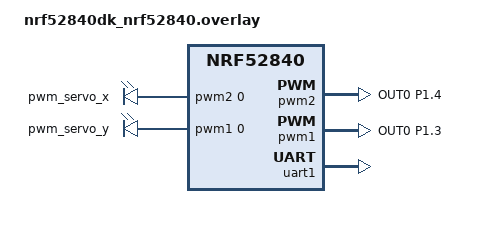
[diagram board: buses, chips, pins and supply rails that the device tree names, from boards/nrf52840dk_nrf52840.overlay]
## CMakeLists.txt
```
cmake_minimum_required(VERSION 3.20.0)
find_package(Zephyr REQUIRED HINTS $ENV{ZEPHYR_BASE})

SET(CMAKE_CXX_STANDARD 17)
SET(CMAKE_CXX_STANDARD_REQUIRED ON)

project(LIDAR_App)

target_sources(app PRIVATE src/main.cpp
                           src/servo.cpp
                           src/lidar.cpp
                           src/Ble.cpp
                           src/LidarService.cpp
)
```

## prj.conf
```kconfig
CONFIG_STDOUT_CONSOLE=y
CONFIG_PRINTK=y
CONFIG_PWM=y
CONFIG_LOG=y
CONFIG_LOG_PRINTK=y
CONFIG_LOG_MODE_IMMEDIATE=y
CONFIG_PWM_LOG_LEVEL_DBG=n

# Serial
CONFIG_UART_INTERRUPT_DRIVEN=y
CONFIG_UART_ASYNC_API=y

# Bluetooth
CONFIG_BT=y
CONFIG_BT_PERIPHERAL=y
CONFIG_BT_DEVICE_NAME="LIDAR_SCANNER"

# CPP
CONFIG_CPP=y
CONFIG_REQUIRES_FULL_LIBCPP=y
CONFIG_CPP_EXCEPTIONS=y
CONFIG_STD_CPP17=y
```

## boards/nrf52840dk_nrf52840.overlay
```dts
/ {
	aliases {
	  pwm-servo-x = &pwm_servo_x;
	  pwm-servo-y = &pwm_servo_y;
    };
  
	pwm-servo-x {
	  compatible = "pwm-leds";
	  pwm_servo_x: pwm_servo_x {
		pwms = <&pwm2 0 PWM_MSEC(20) PWM_POLARITY_NORMAL>;
	  };
	};

	pwm-servo-y {
	  compatible = "pwm-leds";
	  pwm_servo_y: pwm_servo_y {
		pwms = <&pwm1 0 PWM_MSEC(20) PWM_POLARITY_NORMAL>;
	  };
	};
  
  };
  
  &pinctrl {
    pwm1_default: pwm1_default {
        group1 {
            psels = <NRF_PSEL(PWM_OUT0, 1, 3)>;
        };
    };

    pwm2_default: pwm2_default {
        group1 {
            psels = <NRF_PSEL(PWM_OUT0, 1, 4)>;
        };
    };
  };
  
  &pwm2 {
	status = "okay";
	pinctrl-0 = <&pwm2_default>;
	pinctrl-names = "default";
  };

  &pwm1 {
	status = "okay";
	pinctrl-0 = <&pwm1_default>;
	pinctrl-names = "default";
  };

  &pwm0 {
  	status = "disabled";
  };

&uart1 {
	status = "okay";
};

&uart1_default {
	group2 {
		psels = <NRF_PSEL(UART_TX, 1, 6)>;
	};

	group1 {
		psels = <NRF_PSEL(UART_RX, 1, 7)>;
	};
};
```

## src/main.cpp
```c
#include <zephyr/kernel.h>
#include <zephyr/sys/printk.h>
#include <zephyr/device.h>
#include <zephyr/logging/log.h>

#include "../hdr/servo.hpp"
#include "../hdr/lidar.hpp"
#include "../hdr/Ble.h"

#include <vector>
#include <string.h>
#include <string>
#include <sstream>
#include <memory>

LOG_MODULE_REGISTER(main, LOG_LEVEL_INF);

static volatile bool isConnected = false;

std::vector<uint8_t> StructToByteVector(void *structPointer, size_t sizeOfStruct)
{
	std::vector<uint8_t> returnVector;
	returnVector.resize(sizeOfStruct);
	memcpy(&returnVector[0],structPointer,sizeOfStruct); 
	
	return returnVector;
}

const std::vector<uint8_t> vector_to_be_received = {10, 11, 12, 13, 14, 15, 16, 17};

void configCallback(std::vector<uint8_t> data)
{        

	if(data.size() != 8){
			LOG_ERR("Wrong data size\n");
			return;
	}

	for (size_t i = 0; i < vector_to_be_received.size(); ++i)
	{
		if (vector_to_be_received[i] != data[i])
		{
			LOG_INF("Device Parred Incorrectly");
			return;
		}
		LOG_INF("Byte received: %d", data[i]);
	}

	LOG_INF("Device Parred Correctly");
	isConnected = true;
}

int main(void)
{
	pwm_dt_spec pwm_servo_x = PWM_DT_SPEC_GET(DT_ALIAS(pwm_servo_x));
	std::unique_ptr<Servo> servo_x = std::make_unique<Servo>(pwm_servo_x);

	pwm_dt_spec pwm_servo_y = PWM_DT_SPEC_GET(DT_ALIAS(pwm_servo_y));
	std::unique_ptr<Servo> servo_y = std::make_unique<Servo>(pwm_servo_y);

	const struct device *uart_device = DEVICE_DT_GET(DT_NODELABEL(uart1));
	std::unique_ptr<Lidar> lidar = std::make_unique<Lidar>(uart_device);

	servo_x->Callib();
	servo_y->GoTo(45);

	Ble::Initialize();
	std::function<void(std::vector<uint8_t>)> fun(configCallback);
	Ble::RegisterCallback(fun);

	struct dataToSend {
			uint8_t bytes[4] = {0,0,0,0};
	} data;

	k_msleep(1000);
	std::vector<uint8_t> vdata = StructToByteVector(&data, sizeof(dataToSend));

	std::stringstream msg;
	for(auto val : vdata){
			msg >>val;
	}

	uint16_t distance = 0, strength = 0;

	while(true)
	{
		while(isConnected)
		{	
			for(size_t i = 0; i < SERVO_Y_RANGE; i++)
			{
				for(size_t j = 0; j < SERVO_X_RANGE; j++)
				{
					if(lidar->read_data(&distance, &strength))
					{
						LOG_INF("Distance: %d cm", distance);
						LOG_INF("Strength: %d ", strength);

						data.bytes[0] = (distance >> 8) & 0xFF;
						data.bytes[1] = distance & 0xFF;
						data.bytes[2] = (strength >> 8) & 0xFF;
						data.bytes[3] = strength & 0xFF;

						vdata = StructToByteVector(&data, sizeof(dataToSend));
						for(auto val : vdata){
							msg>>val;
						}

						servo_x->StepLeft();

						Ble::Notify(vdata);
						LOG_INF("Sending bytes...");
					}
					k_msleep(500);
				}
				servo_x->Callib();
				servo_y->StepLeft();
			}
			isConnected = false;
		}
		servo_x->Callib();
		servo_y->GoTo(45);
		k_msleep(1000);
	}
}
```

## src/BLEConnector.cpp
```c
#include "../hdr/BLEConnector.h"

LOG_MODULE_REGISTER(blelog, LOG_LEVEL_INF);

int err;
std::stringstream errMessage;

bt_conn *BLEConnector::m_connection = NULL;
bool BLEConnector::m_alreadyInitialized = false;
bool BLEConnector::notificationEnabled = false;

bt_le_adv_param *defaultAdvertismentParameters = BT_LE_ADV_PARAM(
		(BT_LE_ADV_OPT_CONNECTABLE | BT_LE_ADV_OPT_USE_IDENTITY), // connectable advertising and use identity address
		800, // min advertising interval 500ms (800*0.625ms)
		801, // max advertising interval 500.625ms (801*0.625ms)
		NULL); // undirected advertising

void lidarServiceConfigurationChanged(const struct bt_gatt_attr *attr, uint16_t value)
{
	BLEConnector::notificationEnabled = (value == BT_GATT_CCC_NOTIFY);
}

static struct bt_conn_cb connectionCallbacks; 

BLEConnector::BLEConnector(){

	connectionCallbacks.connected = onConnect;
	connectionCallbacks.disconnected = onConnect;

	bt_conn_cb_register(&connectionCallbacks);

	m_advertisementParams = defaultAdvertismentParameters;

	errMessage.str(std::string());

	if(!m_alreadyInitialized){

		m_alreadyInitialized = true;

		err = bt_enable(NULL);
		if (err) {
			errMessage <<"Bluetooth initialization failed (error %d)\n" <<err <<std::endl;
			LOG_ERR("%s",errMessage.str().c_str());
			throw new std::logic_error(errMessage.str());
		}

		LOG_INF("Bluetooth initialized\n");
	}   

	err = bt_le_adv_start(m_advertisementParams, advertisingData, ARRAY_SIZE(advertisingData), scanResponseData, ARRAY_SIZE(scanResponseData));
	if (err) {
		errMessage <<"Advertising failed to start (error " <<err <<")" <<std::endl; 
		LOG_ERR("%s",errMessage.str().c_str());
		throw new std::logic_error(errMessage.str());
	}

    LOG_INF("Advertising\n");	

}

void BLEConnector::onConnect(struct bt_conn *connection, uint8_t error){
	unsigned int key = irq_lock();

	if(m_connection == NULL)
		LOG_INF("BLE connection established");  
	else
		LOG_INF("BLE reconnected");  

	m_connection = bt_conn_ref(connection);	

	if (error) {
        LOG_ERR("Connection error %d", err);
        return;
    }
	
	irq_unlock(key);
}

void BLEConnector::onDisconnect(struct bt_conn *conn, uint8_t reason){		
	unsigned int key = irq_lock();

	switch(reason){
		case 0x13:
			LOG_INF("Disconnected: remote termination\n");  
			break;
		case 0x8:
			LOG_ERR("Disconnected: timeout\n");
			break;
		default:
			LOG_ERR("Disconnected: reason %d\n",reason);  
			break;
	}

	m_connection = NULL;

	irq_unlock(key);
}

bool BLEConnector::IsConnected(){

	return BLEConnector::m_connection != NULL;

}

bool BLEConnector::IsNotifyEnabled(){

	return notificationEnabled;

}
```

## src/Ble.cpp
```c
#include <zephyr/bluetooth/bluetooth.h>
#include <zephyr/bluetooth/hci.h>
#include <zephyr/bluetooth/conn.h>
#include <zephyr/bluetooth/uuid.h>
#include <zephyr/bluetooth/gatt.h>

#include <zephyr/logging/log.h>

#include <stdexcept>

#include "../hdr/Ble.h"
#include "../hdr/LidarService.h"

LOG_MODULE_REGISTER(ble, LOG_LEVEL_INF);

static const struct bt_data advertisingData[] = {
    BT_DATA_BYTES(BT_DATA_FLAGS, (BT_LE_AD_GENERAL | BT_LE_AD_NO_BREDR)),
    BT_DATA(BT_DATA_NAME_COMPLETE, DEVICE_NAME, DEVICE_NAME_LEN),
};

static const struct bt_data serviceData[] = {
    BT_DATA_BYTES(BT_DATA_UUID128_ALL, BT_UUID_LDS_VAL),
};

static void Connected(struct bt_conn *conn, uint8_t err) {

	if (err) {
		LOG_ERR("Connection failed (err %u)\n", err);
		return;
	}

	LOG_INF("Connected\n");

}

static void Disconnected(struct bt_conn *conn, uint8_t reason){

	LOG_INF("Disconnected (reason %u)\n", reason);

}

BT_CONN_CB_DEFINE(connectionCallbacks) = {
	.connected = Connected,
	.disconnected = Disconnected,
};

struct bt_le_adv_param *advertisingParameters = BT_LE_ADV_PARAM(
    (BT_LE_ADV_OPT_CONNECTABLE | BT_LE_ADV_OPT_USE_IDENTITY), // connectable advertising and use identity address
    800, // min advertising interval 500ms (800*0.625ms)
    801, // max advertising interval 500.625ms (801*0.625ms)
    NULL);

void Ble::Initialize(){

    int error;

    error = bt_enable(NULL);
    if(error)
        throw std::runtime_error("BLE was not enabled");

    LOG_INF("Bluetooth enabled");      

    error = bt_le_adv_start(advertisingParameters, advertisingData, ARRAY_SIZE(advertisingData), serviceData, ARRAY_SIZE(serviceData));
    if(error)
        throw std::runtime_error("Advertising did not start");

    LOG_INF("Advertising started");

}

void Ble::Notify(std::vector<uint8_t> data, Characteristic characteristic){

    switch(characteristic){
        case LidarData:
            try{
                LidarService::Notify(data);
            }
            catch(std::runtime_error e){
                LOG_ERR("%s",e.what());
            }
            break;

        default:
            LOG_ERR("Characteristic notifcation not implemented");
            break;
    }

}

void Ble::RegisterCallback(std::function<void(std::vector<uint8_t>)> callback, Characteristic characteristic){

    LOG_INF("Registering callback"); 

    switch(characteristic){
        case LidarConfig:            
            LidarService::RegisterWrite(callback);            
            break;

        default:
            LOG_ERR("Characteristic callback not implemented");
            break;
    }

}
```

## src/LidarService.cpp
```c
#include <zephyr/bluetooth/gatt.h>

#include <zephyr/logging/log.h>

#include <stdexcept>
#include <sstream>
#include <vector>
#include <functional>

#include "../hdr/LidarService.h"

LOG_MODULE_REGISTER(ble_lidar_service, LOG_LEVEL_INF);

static bool notifyEnabled = false;
static std::function<void(std::vector<uint8_t>)> configurationCallback;

static void CccConfigChanged(const struct bt_gatt_attr *attr, uint16_t value)
{
	notifyEnabled = (value == BT_GATT_CCC_NOTIFY);
}

static ssize_t WriteCofigurationCallback(struct bt_conn *conn, const struct bt_gatt_attr *attr, const void *buf, uint16_t len, uint16_t offset, uint8_t flags){

    LOG_INF("Configuration was updated by the client\n");

    std::vector<uint8_t> byteData;
    byteData.resize(len);

    for(int i=0; i<len; i++){
        byteData[i] = ((uint8_t*)buf)[i];
    }

    if(configurationCallback) configurationCallback(byteData);

    return len;
}

/* Service Declaration */
BT_GATT_SERVICE_DEFINE(lidar_service, BT_GATT_PRIMARY_SERVICE(BT_UUID_LDS),
            BT_GATT_CHARACTERISTIC(BT_UUID_LDS_CHAR,
                        BT_GATT_CHRC_READ | BT_GATT_CHRC_NOTIFY,
                        BT_GATT_PERM_READ, NULL, NULL, NULL),

            BT_GATT_CCC(CccConfigChanged, BT_GATT_PERM_READ | BT_GATT_PERM_WRITE),

            BT_GATT_CHARACTERISTIC(BT_UUID_LDS_CFG,
                        BT_GATT_CHRC_READ | BT_GATT_CHRC_WRITE_WITHOUT_RESP,
                        BT_GATT_PERM_WRITE, NULL, WriteCofigurationCallback, NULL), );            

void LidarService::Notify(std::vector<uint8_t> data){
    
    if (!notifyEnabled)
		throw std::runtime_error("Notify is not enabled");	

	int error = bt_gatt_notify(NULL, &lidar_service.attrs[2], &data[0], data.size()*sizeof(uint8_t));
    if(error != 0)
        LOG_ERR("Notify failed (Error %d)",-error);

}

void  LidarService::RegisterWrite(std::function<void(std::vector<uint8_t>)> callback){
    
    configurationCallback = callback;

}
```

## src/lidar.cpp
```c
#include "../hdr/lidar.hpp"

const struct uart_config uart_cfg = {
	.baudrate = 115200,
	.parity = UART_CFG_PARITY_NONE,
	.stop_bits = UART_CFG_STOP_BITS_1,
	.data_bits = UART_CFG_DATA_BITS_8,
	.flow_ctrl = UART_CFG_FLOW_CTRL_NONE
};

Lidar::Lidar(const struct device *uart_dev)
{
    lidar = uart_dev;

    if (!device_is_ready(lidar))
	{
    	printk("Error\n");
	}

	if (uart_configure(lidar, &uart_cfg) == -ENOSYS)
    {
		printk("Error\n");
	}
}

bool Lidar::read_data(uint16_t* distance, uint16_t* strength)
{
    uint32_t checksum = 0;

    for (unsigned int i = 0; i < sizeof(rx_buf); i++)
    {
        uart_poll_in(lidar, &rx_buf[i]);
    }

    for (unsigned int i = 0; i < sizeof(rx_buf) - 1; i++)
    {
        checksum = checksum + rx_buf[i];
    }

    if ( (rx_buf[0] == 0x59) && (rx_buf[1] == 0x59) )//&& ((checksum % 256) == rx_buf[8]) )
    {
        *distance = rx_buf[2] + rx_buf[3] * 256;
        *strength = rx_buf[4] + rx_buf[5] * 256;

        return true;
    }else
    {
        return false;
    }


}
```

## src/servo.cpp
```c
#include "../hdr/servo.hpp"
#include <zephyr/logging/log.h>

#define PERIOD PWM_USEC(20000)
#define PWM_MIN_PULSE_WIDTH PWM_USEC(1000)
#define PWM_MAX_PULSE_WIDTH PWM_USEC(2000)
#define STEP_SIZE PWM_USEC(5.55)

LOG_MODULE_REGISTER(servo, LOG_LEVEL_INF);

Servo::Servo(pwm_dt_spec pwm_servo_input)
{
    pwm_servo = pwm_servo_input;
}

void Servo::Callib()
{
    int err;
    err = pwm_set_dt(&pwm_servo, PERIOD, PWM_MIN_PULSE_WIDTH);
        if (err) {
        LOG_ERR("pwm_set_dt_returned %d", err);
    }
    current_pulse = PWM_MIN_PULSE_WIDTH;
    LOG_INF("Current pulse: %d", current_pulse);
}

void Servo::GoTo(uint32_t angle)
{
    current_pulse = ( (angle % 181) * (PWM_MAX_PULSE_WIDTH - PWM_MIN_PULSE_WIDTH) / 180) + PWM_MIN_PULSE_WIDTH;
    int err;
    err = pwm_set_dt(&pwm_servo, PERIOD, current_pulse);
        if (err) {
        LOG_ERR("pwm_set_dt_returned %d", err);
    }
    LOG_INF("Current pulse: %d", current_pulse);
}


void Servo::StepLeft()
{
    current_pulse = current_pulse + STEP_SIZE;
    if (current_pulse > PWM_MAX_PULSE_WIDTH)
    {
        current_pulse = PWM_MAX_PULSE_WIDTH;
    }
    int err;
    err = pwm_set_dt(&pwm_servo, PERIOD, current_pulse);
        if (err) {
        LOG_ERR("pwm_set_dt_returned %d", err);
    }
    LOG_INF("Current pulse: %d", current_pulse);
}

void Servo::StepRight()
{
    current_pulse = current_pulse - STEP_SIZE;
    if (current_pulse < PWM_MIN_PULSE_WIDTH)
    {
        current_pulse = PWM_MIN_PULSE_WIDTH;
    }
    int err;
    err = pwm_set_dt(&pwm_servo, PERIOD, current_pulse);
        if (err) {
        LOG_ERR("pwm_set_dt_returned %d", err);
    }
    LOG_INF("Current pulse: %d", current_pulse);
}
```
